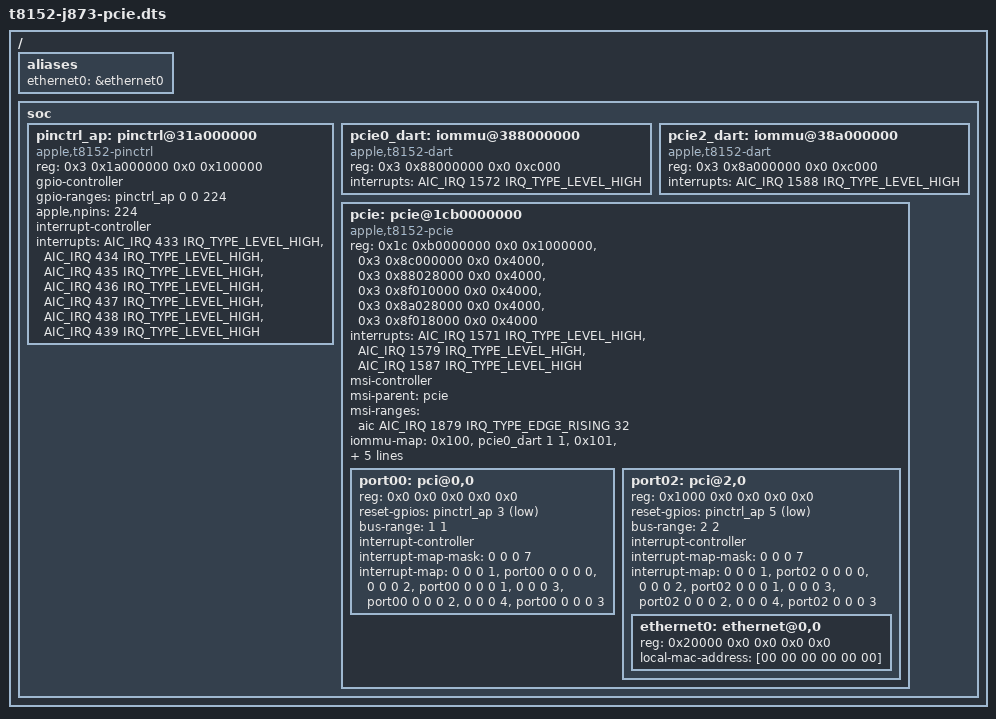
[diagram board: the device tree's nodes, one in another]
// SPDX-License-Identifier: GPL-2.0+ OR MIT
/* J873/T8152 internal PCIe (apcie) bring-up: port 2 carries the on-board
 * 10GbE NIC (ADT /arm-io/apcie/pci-bridge2/lan0; the ADT names an aqc107,
 * the device is a Realtek RTL8127, 10ec:8127). iBoot leaves the APCIE power
 * domains on and the root complex enabled, but the AUS5 PHY gated and the
 * lanes assigned to port 0; the loader (tools/aurora/j873/loader/
 * pcie_prep_j873.py) ungates the PHY and programs lane-cfg first.
 * Port setup follows the T602x/T8122 register layout. Port 0 carries the
 * N1 (Wi-Fi/Bluetooth, ADT pci-bridge0: centauri-control/alpha/beta,
 * functions 0-2, each with its own DART stream).
 * Resources are from the 26A434 ADT: apcie, dart-apcie0, dart-apcie2, gpio0.
 */
#include <dt-bindings/gpio/gpio.h>
#include "t8152-j873-nvme.dts"
#include "t8152-j873-opp.dtsi"

/ {
	aliases {
		ethernet0 = &ethernet0;
	};

	soc {
		pinctrl_ap: pinctrl@31a000000 {
			compatible = "apple,t8152-pinctrl", "apple,t8103-pinctrl";
			reg = <0x3 0x1a000000 0x0 0x100000>;
			gpio-controller;
			#gpio-cells = <2>;
			gpio-ranges = <&pinctrl_ap 0 0 224>;
			apple,npins = <224>;
			interrupt-controller;
			#interrupt-cells = <2>;
			interrupts = <AIC_IRQ 433 IRQ_TYPE_LEVEL_HIGH>,
				     <AIC_IRQ 434 IRQ_TYPE_LEVEL_HIGH>,
				     <AIC_IRQ 435 IRQ_TYPE_LEVEL_HIGH>,
				     <AIC_IRQ 436 IRQ_TYPE_LEVEL_HIGH>,
				     <AIC_IRQ 437 IRQ_TYPE_LEVEL_HIGH>,
				     <AIC_IRQ 438 IRQ_TYPE_LEVEL_HIGH>,
				     <AIC_IRQ 439 IRQ_TYPE_LEVEL_HIGH>;
		};

		pcie0_dart: iommu@388000000 {
			compatible = "apple,t8152-dart", "apple,t8110-dart";
			reg = <0x3 0x88000000 0x0 0xc000>;
			#iommu-cells = <1>;
			interrupts = <AIC_IRQ 1572 IRQ_TYPE_LEVEL_HIGH>;
		};

		pcie2_dart: iommu@38a000000 {
			compatible = "apple,t8152-dart", "apple,t8110-dart";
			reg = <0x3 0x8a000000 0x0 0xc000>;
			#iommu-cells = <1>;
			interrupts = <AIC_IRQ 1588 IRQ_TYPE_LEVEL_HIGH>;
		};

		pcie: pcie@1cb0000000 {
			compatible = "apple,t8152-pcie";
			device_type = "pci";
			reg = <0x1c 0xb0000000 0x0 0x1000000>,	/* config */
			      <0x3 0x8c000000 0x0 0x4000>,	/* rc */
			      <0x3 0x88028000 0x0 0x4000>,	/* port0 */
			      <0x3 0x8f010000 0x0 0x4000>,	/* phy0 */
			      <0x3 0x8a028000 0x0 0x4000>,	/* port2 */
			      <0x3 0x8f018000 0x0 0x4000>;	/* phy2 */
			reg-names = "config", "rc", "port0", "phy0", "port2", "phy2";
			interrupts = <AIC_IRQ 1571 IRQ_TYPE_LEVEL_HIGH>,
				     <AIC_IRQ 1579 IRQ_TYPE_LEVEL_HIGH>,
				     <AIC_IRQ 1587 IRQ_TYPE_LEVEL_HIGH>;
			msi-controller;
			msi-parent = <&pcie>;
			msi-ranges = <&aic AIC_IRQ 1879 IRQ_TYPE_EDGE_RISING 32>;
			/* Port 0 is bus 1 (N1 functions 0-2), port 2 is bus 2. */
			iommu-map = <0x100 &pcie0_dart 1 1>,
				    <0x101 &pcie0_dart 2 1>,
				    <0x102 &pcie0_dart 3 1>,
				    <0x200 &pcie2_dart 1 1>;
			iommu-map-mask = <0xffff>;
			bus-range = <0 7>;
			#address-cells = <3>;
			#size-cells = <2>;
			ranges = <0x43000000 0xb 0xc0000000 0xb 0xc0000000 0x0 0x20000000>,
				 <0x02000000 0x0 0x80000000 0xb 0x80000000 0x0 0x40000000>;

			dma-coherent;

			port00: pci@0,0 {
				device_type = "pci";
				reg = <0x0 0x0 0x0 0x0 0x0>;
				reset-gpios = <&pinctrl_ap 3 GPIO_ACTIVE_LOW>;
				bus-range = <1 1>;
				#address-cells = <3>;
				#size-cells = <2>;
				ranges;

				interrupt-controller;
				#interrupt-cells = <1>;
				interrupt-map-mask = <0 0 0 7>;
				interrupt-map = <0 0 0 1 &port00 0 0 0 0>,
						<0 0 0 2 &port00 0 0 0 1>,
						<0 0 0 3 &port00 0 0 0 2>,
						<0 0 0 4 &port00 0 0 0 3>;
			};

			port02: pci@2,0 {
				device_type = "pci";
				reg = <0x1000 0x0 0x0 0x0 0x0>;
				reset-gpios = <&pinctrl_ap 5 GPIO_ACTIVE_LOW>;
				bus-range = <2 2>;
				#address-cells = <3>;
				#size-cells = <2>;
				ranges;

				interrupt-controller;
				#interrupt-cells = <1>;
				interrupt-map-mask = <0 0 0 7>;
				interrupt-map = <0 0 0 1 &port02 0 0 0 0>,
						<0 0 0 2 &port02 0 0 0 1>,
						<0 0 0 3 &port02 0 0 0 2>,
						<0 0 0 4 &port02 0 0 0 3>;

				ethernet0: ethernet@0,0 {
					reg = <0x20000 0x0 0x0 0x0 0x0>;
					/* Filled in by the loader from the ADT. */
					local-mac-address = [00 00 00 00 00 00];
				};
			};
		};
	};
};
